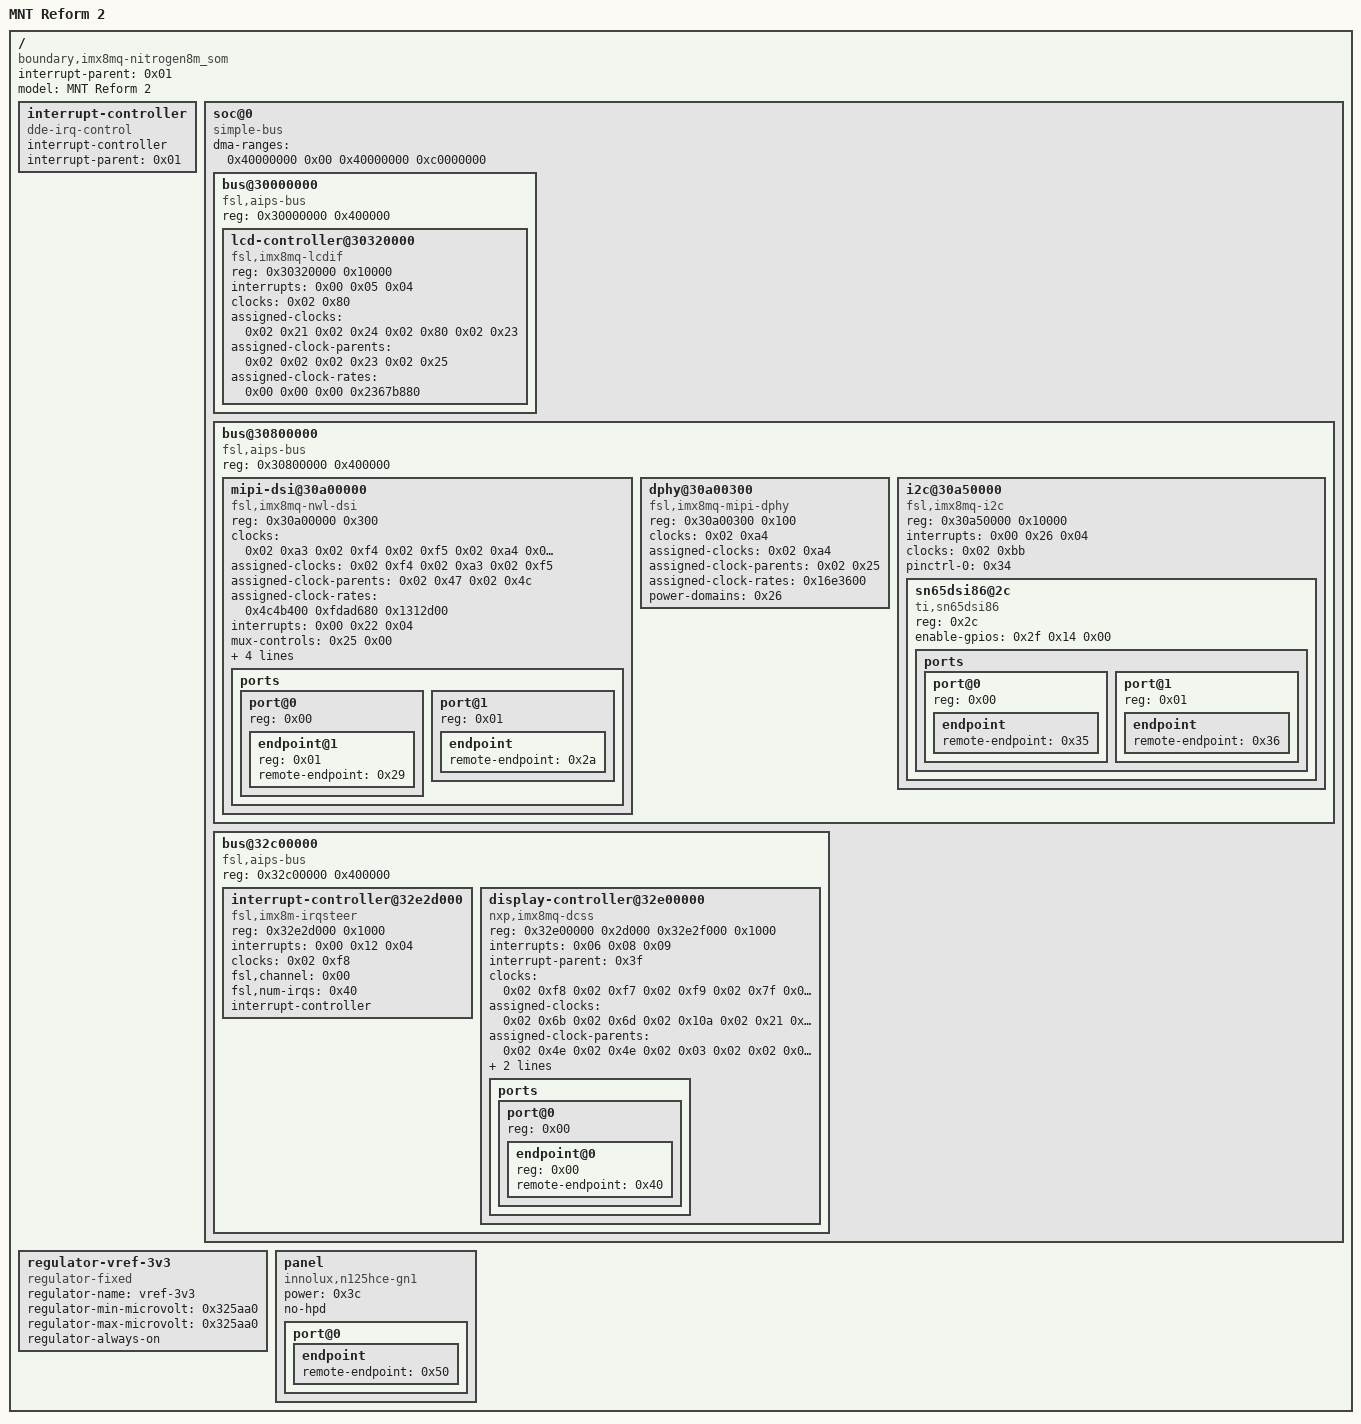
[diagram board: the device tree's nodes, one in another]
/dts-v1/;

/ {
	interrupt-parent = < 0x01 >;
	#address-cells = < 0x02 >;
	#size-cells = < 0x02 >;
	model = "MNT Reform 2";
	compatible = "boundary,imx8mq-nitrogen8m_som\0fsl,imx8mq";

	interrupt-controller {
		compatible = "dde-irq-control";
		#interrupt-cells = < 0x03 >;
		interrupt-controller;
		interrupt-parent = < 0x01 >;
		phandle = < 0x01 >;
	};

	soc@0 {
		compatible = "simple-bus";
		#address-cells = < 0x01 >;
		#size-cells = < 0x01 >;
		ranges = < 0x00 0x00 0x00 0x3e000000 >;
		dma-ranges = < 0x40000000 0x00 0x40000000 0xc0000000 >;

		bus@30000000 {
			compatible = "fsl,aips-bus\0simple-bus";
			reg = < 0x30000000 0x400000 >;
			#address-cells = < 0x01 >;
			#size-cells = < 0x01 >;
			ranges = < 0x30000000 0x30000000 0x400000 >;

			lcd-controller@30320000 {
				compatible = "fsl,imx8mq-lcdif\0fsl,imx28-lcdif";
				reg = < 0x30320000 0x10000 >;
				interrupts = < 0x00 0x05 0x04 >;
				clocks = < 0x02 0x80 >;
				clock-names = "pix";
				assigned-clocks = < 0x02 0x21 0x02 0x24 0x02 0x80 0x02 0x23 >;
				assigned-clock-parents = < 0x02 0x02 0x02 0x23 0x02 0x25 >;
				assigned-clock-rates = < 0x00 0x00 0x00 0x2367b880 >;
				status = "okay";
			};
		};

		bus@30800000 {
			compatible = "fsl,aips-bus\0simple-bus";
			reg = < 0x30800000 0x400000 >;
			#address-cells = < 0x01 >;
			#size-cells = < 0x01 >;
			ranges = < 0x30800000 0x30800000 0x400000 0x8000000 0x8000000 0x10000000 >;

			mipi-dsi@30a00000 {
				compatible = "fsl,imx8mq-nwl-dsi";
				reg = < 0x30a00000 0x300 >;
				clocks = < 0x02 0xa3 0x02 0xf4 0x02 0xf5 0x02 0xa4 0x02 0x80 >;
				clock-names = "core\0rx_esc\0tx_esc\0phy_ref\0lcdif";
				assigned-clocks = < 0x02 0xf4 0x02 0xa3 0x02 0xf5 >;
				assigned-clock-parents = < 0x02 0x47 0x02 0x4c >;
				assigned-clock-rates = < 0x4c4b400 0xfdad680 0x1312d00 >;
				interrupts = < 0x00 0x22 0x04 >;
				mux-controls = < 0x25 0x00 >;
				power-domains = < 0x26 >;
				phys = < 0x27 >;
				phy-names = "dphy";
				resets = < 0x28 0x15 0x28 0x17 0x28 0x18 0x28 0x19 >;
				reset-names = "byte\0dpi\0esc\0pclk";
				status = "okay";

				ports {
					#address-cells = < 0x01 >;
					#size-cells = < 0x00 >;

					port@0 {
						reg = < 0x00 >;
						#address-cells = < 0x01 >;
						#size-cells = < 0x00 >;

						endpoint@1 {
							reg = < 0x01 >;
							remote-endpoint = < 0x29 >;
							phandle = < 0x40 >;
						};
					};

					port@1 {
						reg = < 0x01 >;

						endpoint {
							remote-endpoint = < 0x2a >;
							phandle = < 0x35 >;
						};
					};
				};
			};

			dphy@30a00300 {
				compatible = "fsl,imx8mq-mipi-dphy";
				reg = < 0x30a00300 0x100 >;
				clocks = < 0x02 0xa4 >;
				clock-names = "phy_ref";
				assigned-clocks = < 0x02 0xa4 >;
				assigned-clock-parents = < 0x02 0x25 >;
				assigned-clock-rates = < 0x16e3600 >;
				#phy-cells = < 0x00 >;
				power-domains = < 0x26 >;
				status = "okay";
				phandle = < 0x27 >;
			};

			i2c@30a50000 {
				compatible = "fsl,imx8mq-i2c\0fsl,imx21-i2c";
				reg = < 0x30a50000 0x10000 >;
				interrupts = < 0x00 0x26 0x04 >;
				clocks = < 0x02 0xbb >;
				#address-cells = < 0x01 >;
				#size-cells = < 0x00 >;
				status = "okay";
				pinctrl-names = "default";
				pinctrl-0 = < 0x34 >;

				sn65dsi86@2c {
					compatible = "ti,sn65dsi86";
					reg = < 0x2c >;
					enable-gpios = < 0x2f 0x14 0x00 >;

					ports {
						#address-cells = < 0x01 >;
						#size-cells = < 0x00 >;

						port@0 {
							reg = < 0x00 >;

							endpoint {
								remote-endpoint = < 0x35 >;
								phandle = < 0x2a >;
							};
						};

						port@1 {
							reg = < 0x01 >;

							endpoint {
								remote-endpoint = < 0x36 >;
								phandle = < 0x50 >;
							};
						};
					};
				};
			};
		};

		bus@32c00000 {
			compatible = "fsl,aips-bus\0simple-bus";
			reg = < 0x32c00000 0x400000 >;
			#address-cells = < 0x01 >;
			#size-cells = < 0x01 >;
			ranges = < 0x32c00000 0x32c00000 0x400000 >;

			interrupt-controller@32e2d000 {
				compatible = "fsl,imx8m-irqsteer\0fsl,imx-irqsteer";
				reg = < 0x32e2d000 0x1000 >;
				interrupts = < 0x00 0x12 0x04 >;
				clocks = < 0x02 0xf8 >;
				clock-names = "ipg";
				fsl,channel = < 0x00 >;
				fsl,num-irqs = < 0x40 >;
				interrupt-controller;
				#interrupt-cells = < 0x01 >;
				phandle = < 0x3f >;
			};

			display-controller@32e00000 {
				status = "okay";
				compatible = "nxp,imx8mq-dcss";
				reg = < 0x32e00000 0x2d000 0x32e2f000 0x1000 >;
				interrupts = < 0x06 0x08 0x09 >;
				interrupt-names = "ctxld\0ctxld_kick\0vblank";
				interrupt-parent = < 0x3f >;
				clocks = < 0x02 0xf8 0x02 0xf7 0x02 0xf9 0x02 0x7f 0x02 0x7a 0x02 0x10a 0x02 0x122 >;
				clock-names = "apb\0axi\0rtrm\0pix\0dtrc\0pll_src\0pll_phy_ref";
				assigned-clocks = < 0x02 0x6b 0x02 0x6d 0x02 0x10a 0x02 0x21 0x02 0x7f >;
				assigned-clock-parents = < 0x02 0x4e 0x02 0x4e 0x02 0x03 0x02 0x02 0x02 0x25 >;
				assigned-clock-rates = < 0x2faf0800 0x17d78400 0x19bfcc0 0x17d7840 0x2367b880 >;

				ports {
					#address-cells = < 0x01 >;
					#size-cells = < 0x00 >;

					port@0 {
						reg = < 0x00 >;
						#address-cells = < 0x01 >;
						#size-cells = < 0x00 >;

						endpoint@0 {
							reg = < 0x00 >;
							remote-endpoint = < 0x40 >;
							phandle = < 0x29 >;
						};
					};
				};
			};
		};
	};

	regulator-vref-3v3 {
		compatible = "regulator-fixed";
		regulator-name = "vref-3v3";
		regulator-min-microvolt = < 0x325aa0 >;
		regulator-max-microvolt = < 0x325aa0 >;
		regulator-always-on;
		phandle = < 0x3c >;
	};

	panel {
		compatible = "innolux,n125hce-gn1\0simple-panel";
		power = < 0x3c >;
		no-hpd;

		port@0 {

			endpoint {
				remote-endpoint = < 0x50 >;
				phandle = < 0x36 >;
			};
		};
	};
};
